AUTOSAR XML (schema 4-2-1)
package /MICROSAR/IoHwAb_swc/ComponentTypes
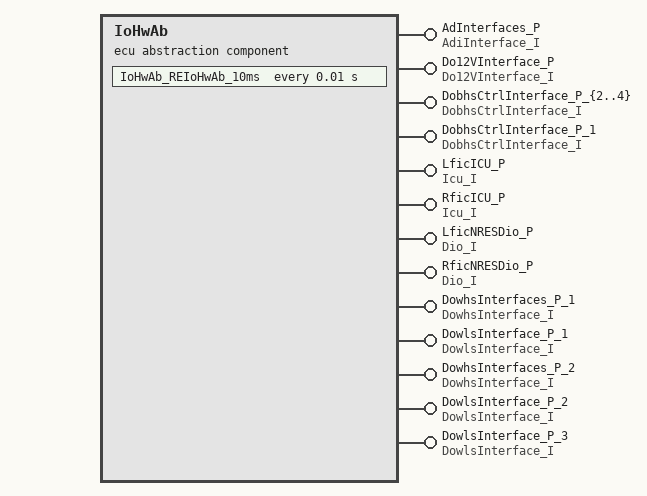
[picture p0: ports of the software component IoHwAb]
  ecu abstraction sw component type IoHwAb
    15 x provide port:
      AdInterfaces_P: provided-interface=AdiInterface_I
      Do12VInterface_P: provided-interface=Do12VInterface_I
      DobhsCtrlInterface_P_{2..4}: provided-interface=DobhsCtrlInterface_I
      DobhsCtrlInterface_P_1: provided-interface=DobhsCtrlInterface_I
      LficICU_P: provided-interface=Icu_I
      RficICU_P: provided-interface=Icu_I
      LficNRESDio_P: provided-interface=Dio_I
      RficNRESDio_P: provided-interface=Dio_I
      DowhsInterfaces_P_1: provided-interface=DowhsInterface_I
      DowlsInterface_P_1: provided-interface=DowlsInterface_I
      DowhsInterfaces_P_2: provided-interface=DowhsInterface_I
      DowlsInterface_P_2: provided-interface=DowlsInterface_I
      DowlsInterface_P_3: provided-interface=DowlsInterface_I
    behavior IoHwAbInternalBehavior: handle-termination-and-restart=NO-SUPPORT
      16 x operation invoked event:
        OpEventIoHwAb_AdInterfaces_P_GetAdiPinState_GetAdiPinState_AdInterfaces_P: start-on-event=IoHwAb_AdInterfaces_P_GetAdiPinState, operation=AdInterfaces_P.GetAdiPinState
        OpEventIoHwAb_AdInterfaces_P_GetAdiPinStateAll_GetAdiPinStateAll_AdInterfaces_P: start-on-event=IoHwAb_AdInterfaces_P_GetAdiPinStateAll, operation=AdInterfaces_P.GetAdiPinStateAll
        OpEventIoHwAb_AdInterfaces_P_GetPullUpState_GetPullUpState_AdInterfaces_P: start-on-event=IoHwAb_AdInterfaces_P_GetPullUpState, operation=AdInterfaces_P.GetPullUpState
        OpEventIoHwAb_AdInterfaces_P_SetPullUp_SetPullUp_AdInterfaces_P: start-on-event=IoHwAb_AdInterfaces_P_SetPullUp, operation=AdInterfaces_P.SetPullUp
        OpEventIoHwAb_Do12VInterface_P_GetDo12VPinsState_GetDo12VPinsState_Do12VInterface_P: start-on-event=IoHwAb_Do12VInterface_P_GetDo12VPinsState, operation=Do12VInterface_P.GetDo12VPinsState
        OpEventIoHwAb_Do12VInterface_P_SetDcdc12VActive_SetDcdc12VActive_Do12VInterface_P: start-on-event=IoHwAb_Do12VInterface_P_SetDcdc12VActive, operation=Do12VInterface_P.SetDcdc12VActive
        OpEventIoHwAb_Do12VInterface_P_SetDo12VLivingActive_SetDo12VLivingActive_Do12VInterface_P: start-on-event=IoHwAb_Do12VInterface_P_SetDo12VLivingActive, operation=Do12VInterface_P.SetDo12VLivingActive
        OpEventIoHwAb_Do12VInterface_P_SetDo12VParkedActive_SetDo12VParkedActive_Do12VInterface_P: start-on-event=IoHwAb_Do12VInterface_P_SetDo12VParkedActive, operation=Do12VInterface_P.SetDo12VParkedActive
        OpEventIoHwAb_DobhsCtrlInterface_P_2_GetDobhsPinState_GetDobhsPinState_DobhsCtrlInterface_P_2: start-on-event=IoHwAb_DobhsCtrlInterface_P_2_GetDobhsPinState, operation=DobhsCtrlInterface_P_2.GetDobhsPinState
        OpEventIoHwAb_DobhsCtrlInterface_P_2_SetDobhsActive_SetDobhsActive_DobhsCtrlInterface_P_2: start-on-event=IoHwAb_DobhsCtrlInterface_P_2_SetDobhsActive, operation=DobhsCtrlInterface_P_2.SetDobhsActive
        OpEventIoHwAb_DobhsCtrlInterface_P_3_GetDobhsPinState_GetDobhsPinState_DobhsCtrlInterface_P_3: start-on-event=IoHwAb_DobhsCtrlInterface_P_3_GetDobhsPinState, operation=DobhsCtrlInterface_P_3.GetDobhsPinState
        OpEventIoHwAb_DobhsCtrlInterface_P_3_SetDobhsActive_SetDobhsActive_DobhsCtrlInterface_P_3: start-on-event=IoHwAb_DobhsCtrlInterface_P_3_SetDobhsActive, operation=DobhsCtrlInterface_P_3.SetDobhsActive
        OpEventIoHwAb_DobhsCtrlInterface_P_4_GetDobhsPinState_GetDobhsPinState_DobhsCtrlInterface_P_4: start-on-event=IoHwAb_DobhsCtrlInterface_P_4_GetDobhsPinState, operation=DobhsCtrlInterface_P_4.GetDobhsPinState
        OpEventIoHwAb_DobhsCtrlInterface_P_4_SetDobhsActive_SetDobhsActive_DobhsCtrlInterface_P_4: start-on-event=IoHwAb_DobhsCtrlInterface_P_4_SetDobhsActive, operation=DobhsCtrlInterface_P_4.SetDobhsActive
        OpEventIoHwAb_DobhsCtrlInterface_P_1_GetDobhsPinState_GetDobhsPinState_DobhsCtrlInterface_P_1: start-on-event=IoHwAb_DobhsCtrlInterface_P_1_GetDobhsPinState, operation=DobhsCtrlInterface_P_1.GetDobhsPinState
        OpEventIoHwAb_DobhsCtrlInterface_P_1_SetDobhsActive_SetDobhsActive_DobhsCtrlInterface_P_1: start-on-event=IoHwAb_DobhsCtrlInterface_P_1_SetDobhsActive, operation=DobhsCtrlInterface_P_1.SetDobhsActive
      timing event Timer_IoHwAb_REIoHwAb_10ms: start-on-event=IoHwAb_REIoHwAb_10ms, period=0.01
      22 x operation invoked event:
        OpEventIoHwAb_LficICU_P_IcuEnableNotification_IcuEnableNotification_LficICU_P: start-on-event=IoHwAb_LficICU_P_IcuEnableNotification, operation=LficICU_P.IcuEnableNotification
        OpEventIoHwAb_LficICU_P_IcuEnableEdgeDetection_IcuEnableEdgeDetection_LficICU_P: start-on-event=IoHwAb_LficICU_P_IcuEnableEdgeDetection, operation=LficICU_P.IcuEnableEdgeDetection
        OpEventIoHwAb_RficICU_P_IcuEnableNotification_IcuEnableNotification_RficICU_P: start-on-event=IoHwAb_RficICU_P_IcuEnableNotification, operation=RficICU_P.IcuEnableNotification
        OpEventIoHwAb_RficICU_P_IcuEnableEdgeDetection_IcuEnableEdgeDetection_RficICU_P: start-on-event=IoHwAb_RficICU_P_IcuEnableEdgeDetection, operation=RficICU_P.IcuEnableEdgeDetection
        OpEventIoHwAb_LficNRESDio_P_Read_Read_LficNRESDio_P: start-on-event=IoHwAb_LficNRESDio_P_Read, operation=LficNRESDio_P.Read
        OpEventIoHwAb_LficNRESDio_P_Write_Write_LficNRESDio_P: start-on-event=IoHwAb_LficNRESDio_P_Write, operation=LficNRESDio_P.Write
        OpEventIoHwAb_LficICU_P_IcuDisableEdgeDetection_IcuDisableEdgeDetection_LficICU_P: start-on-event=IoHwAb_LficICU_P_IcuDisableEdgeDetection, operation=LficICU_P.IcuDisableEdgeDetection
        OpEventIoHwAb_LficICU_P_IcuDisableNotification_IcuDisableNotification_LficICU_P: start-on-event=IoHwAb_LficICU_P_IcuDisableNotification, operation=LficICU_P.IcuDisableNotification
        OpEventIoHwAb_RficICU_P_IcuDisableEdgeDetection_IcuDisableEdgeDetection_RficICU_P: start-on-event=IoHwAb_RficICU_P_IcuDisableEdgeDetection, operation=RficICU_P.IcuDisableEdgeDetection
        OpEventIoHwAb_RficICU_P_IcuDisableNotification_IcuDisableNotification_RficICU_P: start-on-event=IoHwAb_RficICU_P_IcuDisableNotification, operation=RficICU_P.IcuDisableNotification
        OpEventIoHwAb_RficNRESDio_P_Read_Read_RficNRESDio_P: start-on-event=IoHwAb_RficNRESDio_P_Read, operation=RficNRESDio_P.Read
        OpEventIoHwAb_RficNRESDio_P_Write_Write_RficNRESDio_P: start-on-event=IoHwAb_RficNRESDio_P_Write, operation=RficNRESDio_P.Write
        OpEventIoHwAb_DowhsInterfaces_P_1_GetDoPinStateOne_GetDoPinStateOne_DowhsInterfaces_P_1: start-on-event=IoHwAb_DowhsInterfaces_P_1_GetDoPinStateOne, operation=DowhsInterfaces_P_1.GetDoPinStateOne
        OpEventIoHwAb_DowhsInterfaces_P_1_SetDowActive_SetDowActive_DowhsInterfaces_P_1: start-on-event=IoHwAb_DowhsInterfaces_P_1_SetDowActive, operation=DowhsInterfaces_P_1.SetDowActive
        OpEventIoHwAb_DowlsInterface_P_1_GetDoPinStateOne_GetDoPinStateOne_DowlsInterface_P_1: start-on-event=IoHwAb_DowlsInterface_P_1_GetDoPinStateOne, operation=DowlsInterface_P_1.GetDoPinStateOne
        OpEventIoHwAb_DowlsInterface_P_1_SetDowlsActive_SetDowlsActive_DowlsInterface_P_1: start-on-event=IoHwAb_DowlsInterface_P_1_SetDowlsActive, operation=DowlsInterface_P_1.SetDowlsActive
        OpEventIoHwAb_DowhsInterfaces_P_2_GetDoPinStateOne_GetDoPinStateOne_DowhsInterfaces_P_2: start-on-event=IoHwAb_DowhsInterfaces_P_2_GetDoPinStateOne, operation=DowhsInterfaces_P_2.GetDoPinStateOne
        OpEventIoHwAb_DowhsInterfaces_P_2_SetDowActive_SetDowActive_DowhsInterfaces_P_2: start-on-event=IoHwAb_DowhsInterfaces_P_2_SetDowActive, operation=DowhsInterfaces_P_2.SetDowActive
        OpEventIoHwAb_DowlsInterface_P_2_GetDoPinStateOne_GetDoPinStateOne_DowlsInterface_P_2: start-on-event=IoHwAb_DowlsInterface_P_2_GetDoPinStateOne, operation=DowlsInterface_P_2.GetDoPinStateOne
        OpEventIoHwAb_DowlsInterface_P_2_SetDowlsActive_SetDowlsActive_DowlsInterface_P_2: start-on-event=IoHwAb_DowlsInterface_P_2_SetDowlsActive, operation=DowlsInterface_P_2.SetDowlsActive
        OpEventIoHwAb_DowlsInterface_P_3_GetDoPinStateOne_GetDoPinStateOne_DowlsInterface_P_3: start-on-event=IoHwAb_DowlsInterface_P_3_GetDoPinStateOne, operation=DowlsInterface_P_3.GetDoPinStateOne
        OpEventIoHwAb_DowlsInterface_P_3_SetDowlsActive_SetDowlsActive_DowlsInterface_P_3: start-on-event=IoHwAb_DowlsInterface_P_3_SetDowlsActive, operation=DowlsInterface_P_3.SetDowlsActive
      port-api-options:
        enable-take-address=true, indirect-api=false, port=AdInterfaces_P
        enable-take-address=true, indirect-api=false, port=Do12VInterface_P
        enable-take-address=true, indirect-api=false, port=DobhsCtrlInterface_P_{2..4}
        enable-take-address=true, indirect-api=false, port=DobhsCtrlInterface_P_1
        enable-take-address=true, indirect-api=false, port=LficICU_P
        enable-take-address=true, indirect-api=false, port=RficICU_P
        enable-take-address=true, indirect-api=false, port=LficNRESDio_P
        enable-take-address=true, indirect-api=false, port=RficNRESDio_P
        enable-take-address=true, indirect-api=false, port=DowhsInterfaces_P_1
        enable-take-address=true, indirect-api=false, port=DowlsInterface_P_1
        enable-take-address=true, indirect-api=false, port=DowhsInterfaces_P_2
        enable-take-address=true, indirect-api=false, port=DowlsInterface_P_2
        enable-take-address=true, indirect-api=false, port=DowlsInterface_P_3
      39 x runnable, all with can-be-invoked-concurrently=true:
        IoHwAb_AdInterfaces_P_GetAdiPinState  # Runnable Entity for calling the Operation 'GetAdiPinState' of the Client/Server Port Prototype 'AdInterfaces_P'.
        IoHwAb_AdInterfaces_P_GetAdiPinStateAll  # Runnable Entity for calling the Operation 'GetAdiPinStateAll' of the Client/Server Port Prototype 'AdInterfaces_P'.
        IoHwAb_AdInterfaces_P_GetPullUpState  # Runnable Entity for calling the Operation 'GetPullUpState' of the Client/Server Port Prototype 'AdInterfaces_P'.
        IoHwAb_AdInterfaces_P_SetPullUp  # Runnable Entity for calling the Operation 'SetPullUp' of the Client/Server Port Prototype 'AdInterfaces_P'.
        IoHwAb_Do12VInterface_P_GetDo12VPinsState  # Runnable Entity for calling the Operation 'GetDo12VPinsState' of the Client/Server Port Prototype 'Do12VInterface_P'.
        IoHwAb_Do12VInterface_P_SetDcdc12VActive  # Runnable Entity for calling the Operation 'SetDcdc12VActive' of the Client/Server Port Prototype 'Do12VInterface_P'.
        IoHwAb_Do12VInterface_P_SetDo12VLivingActive  # Runnable Entity for calling the Operation 'SetDo12VLivingActive' of the Client/Server Port Prototype 'Do12VInterface_P'.
        IoHwAb_Do12VInterface_P_SetDo12VParkedActive  # Runnable Entity for calling the Operation 'SetDo12VParkedActive' of the Client/Server Port Prototype 'Do12VInterface_P'.
        IoHwAb_DobhsCtrlInterface_P_2_GetDobhsPinState  # Runnable Entity for calling the Operation 'GetDobhsPinState' of the Client/Server Port Prototype 'DobhsCtrlInterface_P_2'.
        IoHwAb_DobhsCtrlInterface_P_2_SetDobhsActive  # Runnable Entity for calling the Operation 'SetDobhsActive' of the Client/Server Port Prototype 'DobhsCtrlInterface_P_2'.
        IoHwAb_DobhsCtrlInterface_P_3_GetDobhsPinState  # Runnable Entity for calling the Operation 'GetDobhsPinState' of the Client/Server Port Prototype 'DobhsCtrlInterface_P_3'.
        IoHwAb_DobhsCtrlInterface_P_3_SetDobhsActive  # Runnable Entity for calling the Operation 'SetDobhsActive' of the Client/Server Port Prototype 'DobhsCtrlInterface_P_3'.
        IoHwAb_DobhsCtrlInterface_P_4_GetDobhsPinState  # Runnable Entity for calling the Operation 'GetDobhsPinState' of the Client/Server Port Prototype 'DobhsCtrlInterface_P_4'.
        IoHwAb_DobhsCtrlInterface_P_4_SetDobhsActive  # Runnable Entity for calling the Operation 'SetDobhsActive' of the Client/Server Port Prototype 'DobhsCtrlInterface_P_4'.
        IoHwAb_DobhsCtrlInterface_P_1_GetDobhsPinState  # Runnable Entity for calling the Operation 'GetDobhsPinState' of the Client/Server Port Prototype 'DobhsCtrlInterface_P_1'.
        IoHwAb_DobhsCtrlInterface_P_1_SetDobhsActive  # Runnable Entity for calling the Operation 'SetDobhsActive' of the Client/Server Port Prototype 'DobhsCtrlInterface_P_1'.
        IoHwAb_REIoHwAb_10ms
        IoHwAb_LficICU_P_IcuEnableNotification  # Runnable Entity for calling the Operation 'IcuEnableNotification' of the Client/Server Port Prototype 'LficICU_P'.
        IoHwAb_LficICU_P_IcuEnableEdgeDetection  # Runnable Entity for calling the Operation 'IcuEnableEdgeDetection' of the Client/Server Port Prototype 'LficICU_P'.
        IoHwAb_RficICU_P_IcuEnableNotification  # Runnable Entity for calling the Operation 'IcuEnableNotification' of the Client/Server Port Prototype 'RficICU_P'.
        IoHwAb_RficICU_P_IcuEnableEdgeDetection  # Runnable Entity for calling the Operation 'IcuEnableEdgeDetection' of the Client/Server Port Prototype 'RficICU_P'.
        IoHwAb_LficNRESDio_P_Read  # Runnable Entity for calling the Operation 'Read' of the Client/Server Port Prototype 'LficNRESDio_P'.
        IoHwAb_LficNRESDio_P_Write  # Runnable Entity for calling the Operation 'Write' of the Client/Server Port Prototype 'LficNRESDio_P'.
        IoHwAb_LficICU_P_IcuDisableEdgeDetection  # Runnable Entity for calling the Operation 'IcuDisableEdgeDetection' of the Client/Server Port Prototype 'LficICU_P'.
        IoHwAb_LficICU_P_IcuDisableNotification  # Runnable Entity for calling the Operation 'IcuDisableNotification' of the Client/Server Port Prototype 'LficICU_P'.
        IoHwAb_RficICU_P_IcuDisableEdgeDetection  # Runnable Entity for calling the Operation 'IcuDisableEdgeDetection' of the Client/Server Port Prototype 'RficICU_P'.
        IoHwAb_RficICU_P_IcuDisableNotification  # Runnable Entity for calling the Operation 'IcuDisableNotification' of the Client/Server Port Prototype 'RficICU_P'.
        IoHwAb_RficNRESDio_P_Read  # Runnable Entity for calling the Operation 'Read' of the Client/Server Port Prototype 'RficNRESDio_P'.
        IoHwAb_RficNRESDio_P_Write  # Runnable Entity for calling the Operation 'Write' of the Client/Server Port Prototype 'RficNRESDio_P'.
        IoHwAb_DowhsInterfaces_P_1_GetDoPinStateOne  # Runnable Entity for calling the Operation 'GetDoPinStateOne' of the Client/Server Port Prototype 'DowhsInterfaces_P_1'.
        IoHwAb_DowhsInterfaces_P_1_SetDowActive  # Runnable Entity for calling the Operation 'SetDowActive' of the Client/Server Port Prototype 'DowhsInterfaces_P_1'.
        IoHwAb_DowlsInterface_P_1_GetDoPinStateOne  # Runnable Entity for calling the Operation 'GetDoPinStateOne' of the Client/Server Port Prototype 'DowlsInterface_P_1'.
        IoHwAb_DowlsInterface_P_1_SetDowlsActive  # Runnable Entity for calling the Operation 'SetDowlsActive' of the Client/Server Port Prototype 'DowlsInterface_P_1'.
        IoHwAb_DowhsInterfaces_P_2_GetDoPinStateOne  # Runnable Entity for calling the Operation 'GetDoPinStateOne' of the Client/Server Port Prototype 'DowhsInterfaces_P_2'.
        IoHwAb_DowhsInterfaces_P_2_SetDowActive  # Runnable Entity for calling the Operation 'SetDowActive' of the Client/Server Port Prototype 'DowhsInterfaces_P_2'.
        IoHwAb_DowlsInterface_P_2_GetDoPinStateOne  # Runnable Entity for calling the Operation 'GetDoPinStateOne' of the Client/Server Port Prototype 'DowlsInterface_P_2'.
        IoHwAb_DowlsInterface_P_2_SetDowlsActive  # Runnable Entity for calling the Operation 'SetDowlsActive' of the Client/Server Port Prototype 'DowlsInterface_P_2'.
        IoHwAb_DowlsInterface_P_3_GetDoPinStateOne  # Runnable Entity for calling the Operation 'GetDoPinStateOne' of the Client/Server Port Prototype 'DowlsInterface_P_3'.
        IoHwAb_DowlsInterface_P_3_SetDowlsActive  # Runnable Entity for calling the Operation 'SetDowlsActive' of the Client/Server Port Prototype 'DowlsInterface_P_3'.
  swc implementation IoHwAbImplementation: programming-language=C, behavior=IoHwAbInternalBehavior
package /MICROSAR/IoHwAb_swc/Interfaces
  10 x client server interface:
    FSC_OperationalMode_I
      operation VbatInterface_P: possible-error=FSC_OperationalMode_I/IoHwAbApplicationError
      operation FSC_OperationalMode: possible-error=FSC_OperationalMode_I/IoHwAbApplicationError
      error IoHwAbApplicationError: error-code=1
    VbatInterface_I
      7 x operation, all with possible-error=VbatInterface_I/IoHwAbApplicationError:
        VbatInterface_P
        FSC_OperationalMode
        DobhsCtrlInterface_P_{1..3}
        DobhsCtrlInterface_P_5
        DobhsCtrlInterface_P_4
      error IoHwAbApplicationError: error-code=1
    DowlsInterface_I
      operation GetDoPinStateOne: possible-error=DowlsInterface_I/IoHwAbApplicationError
        7 x arg:
          DoPinRef: type=IOHWAB_UINT8, direction=IN
          IsDoActivated: type=IOHWAB_BOOL, direction=OUT
          DoPinVoltage: type=IOHWAB_UINT16, direction=OUT
          BatteryVoltage: type=IOHWAB_UINT16, direction=OUT
          DutyCycle: type=IOHWAB_UINT8, direction=OUT
          Period: type=IOHWAB_UINT16, direction=OUT
          DiagStatus: type=VGTT_EcuPinDiagStatus, direction=OUT
      operation SetDowlsActive: possible-error=DowlsInterface_I/IoHwAbApplicationError
        arg OutputId: type=IOHWAB_UINT8, direction=IN
        arg Period: type=IOHWAB_UINT16, direction=IN
        arg DutyCycle: type=IOHWAB_SINT8, direction=IN
      error IoHwAbApplicationError: error-code=1
    DobhsCtrlInterface_I
      operation GetDobhsPinState: possible-error=DobhsCtrlInterface_I/IoHwAbApplicationError
        4 x arg, all with direction=OUT:
          IsDoActivated: type=IOHWAB_BOOL
          DoPinVoltage: type=IOHWAB_UINT16
          BatteryVoltage: type=IOHWAB_UINT16
          DiagStatus: type=VGTT_EcuPinDiagStatus
      operation SetDobhsActive: possible-error=DobhsCtrlInterface_I/IoHwAbApplicationError
        arg Activation: type=IOHWAB_BOOL, direction=IN
      error IoHwAbApplicationError: error-code=1
    AdiInterface_I
      4 x operation, all with possible-error=AdiInterface_I/IoHwAbApplicationError:
        GetAdiPinState
          arg AdiPinRef: type=IOHWAB_UINT8, direction=IN
          arg AdiPinVoltage: type=IOHWAB_UINT16, direction=OUT
          arg LivingPullUpVoltage: type=VGTT_EcuPinVoltage_0V2, direction=OUT
        GetAdiPinStateAll
          arg VoltageOnAdiPins: type=VGTT_ScimAdiPinsState, direction=OUT
          arg LivingPullUpVoltage: type=VGTT_EcuPinVoltage_0V2, direction=OUT
        GetPullUpState
          4 x arg, all with type=VGTT_EcuPinVoltage_0V2, direction=OUT:
            PullUpVoltage_Living
            PullUpVoltage_Parked
            PullUpVoltage_DAI1
            PullUpVoltage_DAI2
        SetPullUp
          arg ActivateLivingPullUp: type=IOHWAB_BOOL, direction=IN
          arg ActivateParkedPullUp: type=IOHWAB_BOOL, direction=IN
          arg ActivateDAIPullUp: type=IOHWAB_BOOL, direction=IN
      error IoHwAbApplicationError: error-code=1
    Do12VInterface_I
      4 x operation, all with possible-error=Do12VInterface_I/IoHwAbApplicationError:
        GetDo12VPinsState
          6 x arg:
            SelectParkedOrLivingPin: type=IOHWAB_UINT8, direction=IN
            IsDo12VActivated: type=IOHWAB_BOOL, direction=OUT
            Do12VPinVoltage: type=VGTT_EcuPinVoltage_0V2, direction=OUT
            BatteryVoltage: type=IOHWAB_UINT16, direction=OUT
            DcdcRefVoltage: type=VGTT_EcuPinVoltage_0V2, direction=OUT
            DiagStatus: type=VGTT_EcuPinDiagStatus, direction=OUT
        SetDcdc12VActive
          arg Activation: type=IOHWAB_BOOL, direction=IN
        SetDo12VLivingActive
          arg Activation: type=IOHWAB_BOOL, direction=IN
        SetDo12VParkedActive
          arg Activation: type=IOHWAB_BOOL, direction=IN
      error IoHwAbApplicationError: error-code=1
    DobhsDiagInterface_I
      operation IoHwAbOperation: possible-error=DobhsDiagInterface_I/IoHwAbApplicationError
      error IoHwAbApplicationError: error-code=1
    DowhsInterface_I
      operation GetDoPinStateOne: possible-error=DowhsInterface_I/IoHwAbApplicationError
        7 x arg:
          DoPinRef: type=IOHWAB_UINT8, direction=IN
          IsDoActivated: type=IOHWAB_BOOL, direction=OUT
          DoPinVoltage: type=IOHWAB_UINT16, direction=OUT
          BatteryVoltage: type=IOHWAB_UINT16, direction=OUT
          DutyCycle: type=IOHWAB_UINT8, direction=OUT
          Period: type=IOHWAB_UINT16, direction=OUT
          DiagStatus: type=VGTT_EcuPinDiagStatus, direction=OUT
      operation SetDowActive: possible-error=DowhsInterface_I/IoHwAbApplicationError
        arg OutputId: type=IOHWAB_UINT8, direction=IN
        arg Period: type=IOHWAB_UINT16, direction=IN
        arg DutyCycle: type=IOHWAB_UINT8, direction=IN
      error IoHwAbApplicationError: error-code=1
    Icu_I
      4 x operation, all with possible-error=Icu_I/IoHwAbApplicationError:
        IcuEnableNotification
        IcuEnableEdgeDetection
        IcuDisableEdgeDetection
        IcuDisableNotification
      error IoHwAbApplicationError: error-code=1
    Dio_I
      operation Read: possible-error=Dio_I/IoHwAbApplicationError
        arg ReadValue: type=IOHWAB_UINT8, direction=OUT
      operation Write: possible-error=Dio_I/IoHwAbApplicationError
        arg SetValue: type=IOHWAB_UINT8, direction=IN
      error IoHwAbApplicationError: error-code=1
package /MICROSAR/IoHwAb_swc/DataTypes
  7 x impl type, all with category=TYPE_REFERENCE:
    IOHWAB_UINT8: range raw 0..255, implementation-data-type=uint8
    IOHWAB_SINT8: range raw -128..127, implementation-data-type=sint8
    IOHWAB_UINT16: range raw 0..65535, implementation-data-type=uint16
    IOHWAB_BOOL: implementation-data-type=boolean
    VGTT_EcuPinVoltage_0V2: implementation-data-type=IOHWAB_UINT8
    VGTT_ScimAdiPinsState: implementation-data-type=IOHWAB_UINT16
    VGTT_EcuPinDiagStatus: implementation-data-type=IOHWAB_UINT8
